# SD24_A2_2 register map
Vendor: Texas Instruments
Peripheral module from a debugger description file (folder msp430).
Registers are 16-bit, read-write, reset 0x0 unless marked. A register's access mark holds for its fields unless they carry their own. Offsets are as the file gives them; lines under a group give offsets from that group; [hi:lo] are bit positions; {n}, {i} and the like mark numbered series; 'fields as' and 'values as' point back to an identical list; <NAME> marks a mode.

## SD24_A2
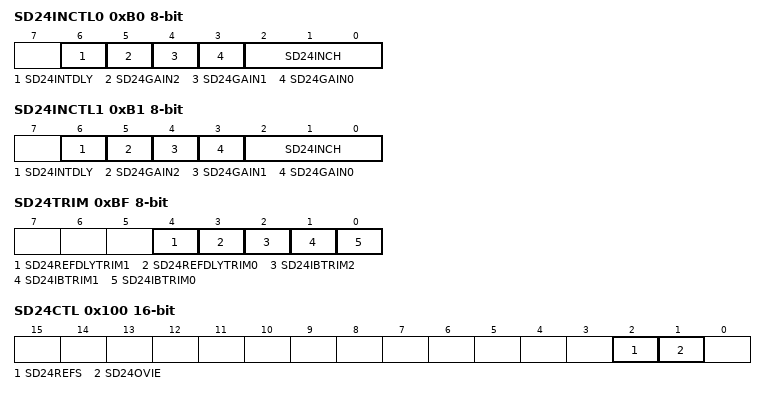
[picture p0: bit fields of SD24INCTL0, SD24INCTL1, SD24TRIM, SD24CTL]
0xB0 SD24INCTL0 8-bit — SD24 Input Control Register Channel 0
  [6] SD24INTDLY — SD24 Interrupt Delay after 1.Conversion
  [5] SD24GAIN2 — SD24 Input Pre-Amplifier Gain Select 2
  [4] SD24GAIN1 — SD24 Input Pre-Amplifier Gain Select 1
  [3] SD24GAIN0 — SD24 Input Pre-Amplifier Gain Select 0
  [2:0] SD24INCH — SD24 Input Channel select 0
    {v}=SD24 Input Channel select input (v=0..4); 5=SD24 Input Channel select Vcc divider; 6=SD24 Input Channel select Temp; 7=SD24 Input Channel select Offset
0xB1 SD24INCTL1 8-bit — SD24 Input Control Register Channel 1
  fields as SD24INCTL0
0xB8 SD24PRE0 8-bit access not given reset not defined — SD24 Preload Register Channel 0
0xB9 SD24PRE1 8-bit access not given reset not defined — SD24 Preload Register Channel 1
0xBF SD24TRIM 8-bit — SD24 Trim Register 1
  [4] SD24REFDLYTRIM1 — SD24 Trimming of reference voltage buffer start up delay Bit: 1
  [3] SD24REFDLYTRIM0 — SD24 Trimming of reference voltage buffer start up delay Bit: 0
  [2] SD24IBTRIM2 — SD24 Trimming of bias current Bit: 2
  [1] SD24IBTRIM1 — SD24 Trimming of bias current Bit: 1
  [0] SD24IBTRIM0 — SD24 Trimming of bias current Bit: 0
0x100 SD24CTL — Sigma Delta ADC 24 Control Register
  [2] SD24REFS — SD24 Reference Select
  [1] SD24OVIE — SD24 Overflow Interupt Enable
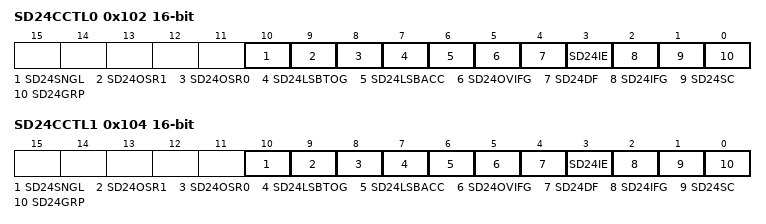
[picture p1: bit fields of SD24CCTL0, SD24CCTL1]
0x102 SD24CCTL0 — SD24 Channel 0 Control Register
  [10] SD24SNGL — SD24 Channel x Single Conversion On/Off
  [9] SD24OSR1 — SD24 Channel x OverSampling Ratio 1
  [8] SD24OSR0 — SD24 Channel x OverSampling Ratio 0
  [7] SD24LSBTOG — SD24 Channel x Toggle LSB Output of ADC
  [6] SD24LSBACC — SD24 Channel x Access LSB of ADC
  [5] SD24OVIFG — SD24 Channel x Overflow Interrupt Flag
  [4] SD24DF — SD24 Channel x Data Format: 0:Unipolar/1:Bipolar
  [3] SD24IE — SD24 Channel x Interrupt Enable
  [2] SD24IFG — SD24 Channel x Interrupt Flag
  [1] SD24SC — SD24 Start Conversion
  [0] SD24GRP — SD24 Grouping of Channels: 0:Off/1:On
0x104 SD24CCTL1 — SD24 Channel 1 Control Register
  fields as SD24CCTL0
0x110 SD24MEM0 access not given reset not defined — SD24 Channel 0 Conversion Memory
0x112 SD24MEM1 access not given reset not defined — SD24 Channel 1 Conversion Memory
0x1F0 SD24IV access not given reset not defined — SD24 Interrupt Vector Register
